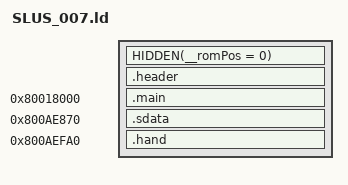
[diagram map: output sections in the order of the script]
SECTIONS
{
    HIDDEN(__romPos = 0);
    _gp = 0x800AE870;
    header_ROM_START = __romPos;
    header_VRAM = ADDR(.header);
    .header : AT(header_ROM_START) SUBALIGN(16)
    {
        FILL(0x00000000);
        header_DATA_START = .;
        build/assets/header.bin.o(.data);
        header_DATA_END = .;
        header_DATA_SIZE = ABSOLUTE(header_DATA_END - header_DATA_START);
    }
    __romPos += SIZEOF(.header);
    header_ROM_END = __romPos;
    header_VRAM_END = .;

    main_ROM_START = __romPos;
    main_VRAM = ADDR(.main);
    .main 0x80018000 : AT(main_ROM_START) SUBALIGN(4)
    {
        FILL(0x00000000);
        main_TEXT_START = .;
        build/asm/snrelmod.s.o(.text);
        build/asm/main.s.o(.text);
        build/asm/qfr_sing.s.o(.text);
        build/asm/qflypick.s.o(.text);
        build/asm/helpcomp.s.o(.text);
        build/asm/imission.s.o(.text);
        build/asm/qmbase.s.o(.text);
        build/asm/qmjail.s.o(.text);
        build/asm/qmpower.s.o(.text);
        build/asm/qmgrav.s.o(.text);
        build/asm/qmboss.s.o(.text);
        build/asm/qmtrib.s.o(.text);
        build/asm/event.s.o(.text);
        build/asm/qevent.s.o(.text);
        build/asm/event_2.s.o(.text);
        build/asm/qevent_2.s.o(.text);
        build/asm/event_3.s.o(.text);
        build/asm/qevent_3.s.o(.text);
        build/asm/event_4.s.o(.text);
        build/asm/qevent_4.s.o(.text);
        build/asm/event_5.s.o(.text);
        build/asm/qevent_5.s.o(.text);
        build/asm/event_6.s.o(.text);
        build/asm/qevent_6.s.o(.text);
        build/asm/event_7.s.o(.text);
        build/asm/qevent_7.s.o(.text);
        build/asm/event_8.s.o(.text);
        build/asm/qevent_8.s.o(.text);
        build/asm/event_9.s.o(.text);
        build/asm/blur.s.o(.text);
        build/asm/particle.s.o(.text);
        build/asm/q2muzzle.s.o(.text);
        build/asm/input.s.o(.text);
        build/asm/qpanel.s.o(.text);
        build/asm/camera.s.o(.text);
        build/asm/qcamera.s.o(.text);
        build/asm/mainloop.s.o(.text);
        build/asm/qloop.s.o(.text);
        build/asm/qplayer.s.o(.text);
        build/asm/quake.s.o(.text);
        build/asm/game.s.o(.text);
        build/asm/spritext.s.o(.text);
        build/asm/scrnshot.s.o(.text);
        build/asm/gunsight.s.o(.text);
        build/asm/col3d.s.o(.text);
        build/asm/move3d.s.o(.text);
        build/asm/sort.s.o(.text);
        build/asm/missile.s.o(.text);
        build/asm/quakemis.s.o(.text);
        build/asm/quakegun.s.o(.text);
        build/asm/coll.s.o(.text);
        build/asm/mymatrix.s.o(.text);
        build/asm/mymath.s.o(.text);
        build/asm/creature.s.o(.text);
        build/asm/quakecre.s.o(.text);
        build/asm/q_shared.s.o(.text);
        build/asm/g_ai.s.o(.text);
        build/asm/g_misc.s.o(.text);
        build/asm/g_utils.s.o(.text);
        build/asm/m_move.s.o(.text);
        build/asm/p_trail.s.o(.text);
        build/asm/g_weapon.s.o(.text);
        build/asm/gmonster.s.o(.text);
        build/asm/g_combat.s.o(.text);
        build/asm/p_weapon.s.o(.text);
        build/asm/water.s.o(.text);
        build/asm/genefect.s.o(.text);
        build/asm/scene.s.o(.text);
        build/asm/iffload.s.o(.text);
        build/asm/subdiv.s.o(.text);
        build/asm/subdiv2.s.o(.text);
        build/asm/quatanim.s.o(.text);
        build/asm/models.s.o(.text);
        build/asm/title.s.o(.text);
        build/asm/cutquake.s.o(.text);
        build/asm/mymalloc.s.o(.text);
        build/asm/common.s.o(.text);
        build/asm/misc.s.o(.text);
        build/asm/initlev.s.o(.text);
        build/asm/cdaudio.s.o(.text);
        build/asm/nsound.s.o(.text);
        build/asm/lights.s.o(.text);
        build/asm/pal.s.o(.text);
        build/asm/cdstuff.s.o(.text);
        build/asm/draw.s.o(.text);
        build/asm/shadow.s.o(.text);
        build/asm/loadlev.s.o(.text);
        build/asm/qents.s.o(.text);
        build/asm/memory.s.o(.text);
        build/asm/memcard.s.o(.text);
        build/asm/lib_80082b84.s.o(.text);
        main_TEXT_END = .;
        main_TEXT_SIZE = ABSOLUTE(main_TEXT_END - main_TEXT_START);
        main_DATA_START = .;
        build/asm/snrelmod.s.o(.data);
        build/asm/main.s.o(.data);
        build/asm/qfr_sing.s.o(.data);
        build/asm/qflypick.s.o(.data);
        build/asm/helpcomp.s.o(.data);
        build/asm/imission.s.o(.data);
        build/asm/qmbase.s.o(.data);
        build/asm/qmjail.s.o(.data);
        build/asm/qmpower.s.o(.data);
        build/asm/qmgrav.s.o(.data);
        build/asm/qmboss.s.o(.data);
        build/asm/qmtrib.s.o(.data);
        build/asm/event.s.o(.data);
        build/asm/qevent.s.o(.data);
        build/asm/event_2.s.o(.data);
        build/asm/qevent_2.s.o(.data);
        build/asm/event_3.s.o(.data);
        build/asm/qevent_3.s.o(.data);
        build/asm/event_4.s.o(.data);
        build/asm/qevent_4.s.o(.data);
        build/asm/event_5.s.o(.data);
        build/asm/qevent_5.s.o(.data);
        build/asm/event_6.s.o(.data);
        build/asm/qevent_6.s.o(.data);
        build/asm/event_7.s.o(.data);
        build/asm/qevent_7.s.o(.data);
        build/asm/event_8.s.o(.data);
        build/asm/qevent_8.s.o(.data);
        build/asm/event_9.s.o(.data);
        build/asm/blur.s.o(.data);
        build/asm/particle.s.o(.data);
        build/asm/q2muzzle.s.o(.data);
        build/asm/input.s.o(.data);
        build/asm/qpanel.s.o(.data);
        build/asm/camera.s.o(.data);
        build/asm/qcamera.s.o(.data);
        build/asm/mainloop.s.o(.data);
        build/asm/qloop.s.o(.data);
        build/asm/qplayer.s.o(.data);
        build/asm/quake.s.o(.data);
        build/asm/game.s.o(.data);
        build/asm/spritext.s.o(.data);
        build/asm/scrnshot.s.o(.data);
        build/asm/gunsight.s.o(.data);
        build/asm/col3d.s.o(.data);
        build/asm/move3d.s.o(.data);
        build/asm/sort.s.o(.data);
        build/asm/missile.s.o(.data);
        build/asm/quakemis.s.o(.data);
        build/asm/quakegun.s.o(.data);
        build/asm/coll.s.o(.data);
        build/asm/mymatrix.s.o(.data);
        build/asm/mymath.s.o(.data);
        build/asm/creature.s.o(.data);
        build/asm/quakecre.s.o(.data);
        build/asm/q_shared.s.o(.data);
        build/asm/g_ai.s.o(.data);
        build/asm/g_misc.s.o(.data);
        build/asm/g_utils.s.o(.data);
        build/asm/m_move.s.o(.data);
        build/asm/p_trail.s.o(.data);
        build/asm/g_weapon.s.o(.data);
        build/asm/gmonster.s.o(.data);
        build/asm/g_combat.s.o(.data);
        build/asm/p_weapon.s.o(.data);
        build/asm/water.s.o(.data);
        build/asm/genefect.s.o(.data);
        build/asm/scene.s.o(.data);
        build/asm/iffload.s.o(.data);
        build/asm/subdiv.s.o(.data);
        build/asm/subdiv2.s.o(.data);
        build/asm/quatanim.s.o(.data);
        build/asm/models.s.o(.data);
        build/asm/title.s.o(.data);
        build/asm/cutquake.s.o(.data);
        build/asm/mymalloc.s.o(.data);
        build/asm/common.s.o(.data);
        build/asm/misc.s.o(.data);
        build/asm/initlev.s.o(.data);
        build/asm/cdaudio.s.o(.data);
        build/asm/nsound.s.o(.data);
        build/asm/lights.s.o(.data);
        build/asm/pal.s.o(.data);
        build/asm/cdstuff.s.o(.data);
        build/asm/draw.s.o(.data);
        build/asm/shadow.s.o(.data);
        build/asm/loadlev.s.o(.data);
        build/asm/qents.s.o(.data);
        build/asm/memory.s.o(.data);
        build/asm/memcard.s.o(.data);
        build/asm/lib_80082b84.s.o(.data);
        build/asm/data/data.data.s.o(.data);
        main_DATA_END = .;
        main_DATA_SIZE = ABSOLUTE(main_DATA_END - main_DATA_START);
        main_RODATA_START = .;
        build/asm/snrelmod.s.o(.rodata);
        build/asm/main.s.o(.rodata);
        build/asm/qfr_sing.s.o(.rodata);
        build/asm/qflypick.s.o(.rodata);
        build/asm/helpcomp.s.o(.rodata);
        build/asm/imission.s.o(.rodata);
        build/asm/qmbase.s.o(.rodata);
        build/asm/qmjail.s.o(.rodata);
        build/asm/qmpower.s.o(.rodata);
        build/asm/qmgrav.s.o(.rodata);
        build/asm/qmboss.s.o(.rodata);
        build/asm/qmtrib.s.o(.rodata);
        build/asm/event.s.o(.rodata);
        build/asm/qevent.s.o(.rodata);
        build/asm/event_2.s.o(.rodata);
        build/asm/qevent_2.s.o(.rodata);
        build/asm/event_3.s.o(.rodata);
        build/asm/qevent_3.s.o(.rodata);
        build/asm/event_4.s.o(.rodata);
        build/asm/qevent_4.s.o(.rodata);
        build/asm/event_5.s.o(.rodata);
        build/asm/qevent_5.s.o(.rodata);
        build/asm/event_6.s.o(.rodata);
        build/asm/qevent_6.s.o(.rodata);
        build/asm/event_7.s.o(.rodata);
        build/asm/qevent_7.s.o(.rodata);
        build/asm/event_8.s.o(.rodata);
        build/asm/qevent_8.s.o(.rodata);
        build/asm/event_9.s.o(.rodata);
        build/asm/blur.s.o(.rodata);
        build/asm/particle.s.o(.rodata);
        build/asm/q2muzzle.s.o(.rodata);
        build/asm/input.s.o(.rodata);
        build/asm/qpanel.s.o(.rodata);
        build/asm/camera.s.o(.rodata);
        build/asm/qcamera.s.o(.rodata);
        build/asm/mainloop.s.o(.rodata);
        build/asm/qloop.s.o(.rodata);
        build/asm/qplayer.s.o(.rodata);
        build/asm/quake.s.o(.rodata);
        build/asm/game.s.o(.rodata);
        build/asm/spritext.s.o(.rodata);
        build/asm/scrnshot.s.o(.rodata);
        build/asm/gunsight.s.o(.rodata);
        build/asm/col3d.s.o(.rodata);
        build/asm/move3d.s.o(.rodata);
        build/asm/sort.s.o(.rodata);
        build/asm/missile.s.o(.rodata);
        build/asm/quakemis.s.o(.rodata);
        build/asm/quakegun.s.o(.rodata);
        build/asm/coll.s.o(.rodata);
        build/asm/mymatrix.s.o(.rodata);
        build/asm/mymath.s.o(.rodata);
        build/asm/creature.s.o(.rodata);
        build/asm/quakecre.s.o(.rodata);
        build/asm/q_shared.s.o(.rodata);
        build/asm/g_ai.s.o(.rodata);
        build/asm/g_misc.s.o(.rodata);
        build/asm/g_utils.s.o(.rodata);
        build/asm/m_move.s.o(.rodata);
        build/asm/p_trail.s.o(.rodata);
        build/asm/g_weapon.s.o(.rodata);
        build/asm/gmonster.s.o(.rodata);
        build/asm/g_combat.s.o(.rodata);
        build/asm/p_weapon.s.o(.rodata);
        build/asm/water.s.o(.rodata);
        build/asm/genefect.s.o(.rodata);
        build/asm/scene.s.o(.rodata);
        build/asm/iffload.s.o(.rodata);
        build/asm/subdiv.s.o(.rodata);
        build/asm/subdiv2.s.o(.rodata);
        build/asm/quatanim.s.o(.rodata);
        build/asm/models.s.o(.rodata);
        build/asm/title.s.o(.rodata);
        build/asm/cutquake.s.o(.rodata);
        build/asm/mymalloc.s.o(.rodata);
        build/asm/common.s.o(.rodata);
        build/asm/misc.s.o(.rodata);
        build/asm/initlev.s.o(.rodata);
        build/asm/cdaudio.s.o(.rodata);
        build/asm/nsound.s.o(.rodata);
        build/asm/lights.s.o(.rodata);
        build/asm/pal.s.o(.rodata);
        build/asm/cdstuff.s.o(.rodata);
        build/asm/draw.s.o(.rodata);
        build/asm/shadow.s.o(.rodata);
        build/asm/loadlev.s.o(.rodata);
        build/asm/qents.s.o(.rodata);
        build/asm/memory.s.o(.rodata);
        build/asm/memcard.s.o(.rodata);
        build/asm/lib_80082b84.s.o(.rodata);
        build/asm/data/rodata.rodata.s.o(.rodata);
        main_RODATA_END = .;
        main_RODATA_SIZE = ABSOLUTE(main_RODATA_END - main_RODATA_START);
        main_BSS_START = .;
        build/asm/snrelmod.s.o(.bss);
        build/asm/main.s.o(.bss);
        build/asm/qfr_sing.s.o(.bss);
        build/asm/qflypick.s.o(.bss);
        build/asm/helpcomp.s.o(.bss);
        build/asm/imission.s.o(.bss);
        build/asm/qmbase.s.o(.bss);
        build/asm/qmjail.s.o(.bss);
        build/asm/qmpower.s.o(.bss);
        build/asm/qmgrav.s.o(.bss);
        build/asm/qmboss.s.o(.bss);
        build/asm/qmtrib.s.o(.bss);
        build/asm/event.s.o(.bss);
        build/asm/qevent.s.o(.bss);
        build/asm/event_2.s.o(.bss);
        build/asm/qevent_2.s.o(.bss);
        build/asm/event_3.s.o(.bss);
        build/asm/qevent_3.s.o(.bss);
        build/asm/event_4.s.o(.bss);
        build/asm/qevent_4.s.o(.bss);
        build/asm/event_5.s.o(.bss);
        build/asm/qevent_5.s.o(.bss);
        build/asm/event_6.s.o(.bss);
        build/asm/qevent_6.s.o(.bss);
        build/asm/event_7.s.o(.bss);
        build/asm/qevent_7.s.o(.bss);
        build/asm/event_8.s.o(.bss);
        build/asm/qevent_8.s.o(.bss);
        build/asm/event_9.s.o(.bss);
        build/asm/blur.s.o(.bss);
        build/asm/particle.s.o(.bss);
        build/asm/q2muzzle.s.o(.bss);
        build/asm/input.s.o(.bss);
        build/asm/qpanel.s.o(.bss);
        build/asm/camera.s.o(.bss);
        build/asm/qcamera.s.o(.bss);
        build/asm/mainloop.s.o(.bss);
        build/asm/qloop.s.o(.bss);
        build/asm/qplayer.s.o(.bss);
        build/asm/quake.s.o(.bss);
        build/asm/game.s.o(.bss);
        build/asm/spritext.s.o(.bss);
        build/asm/scrnshot.s.o(.bss);
        build/asm/gunsight.s.o(.bss);
        build/asm/col3d.s.o(.bss);
        build/asm/move3d.s.o(.bss);
        build/asm/sort.s.o(.bss);
        build/asm/missile.s.o(.bss);
        build/asm/quakemis.s.o(.bss);
        build/asm/quakegun.s.o(.bss);
        build/asm/coll.s.o(.bss);
        build/asm/mymatrix.s.o(.bss);
        build/asm/mymath.s.o(.bss);
        build/asm/creature.s.o(.bss);
        build/asm/quakecre.s.o(.bss);
        build/asm/q_shared.s.o(.bss);
        build/asm/g_ai.s.o(.bss);
        build/asm/g_misc.s.o(.bss);
        build/asm/g_utils.s.o(.bss);
        build/asm/m_move.s.o(.bss);
        build/asm/p_trail.s.o(.bss);
        build/asm/g_weapon.s.o(.bss);
        build/asm/gmonster.s.o(.bss);
        build/asm/g_combat.s.o(.bss);
        build/asm/p_weapon.s.o(.bss);
        build/asm/water.s.o(.bss);
        build/asm/genefect.s.o(.bss);
        build/asm/scene.s.o(.bss);
        build/asm/iffload.s.o(.bss);
        build/asm/subdiv.s.o(.bss);
        build/asm/subdiv2.s.o(.bss);
        build/asm/quatanim.s.o(.bss);
        build/asm/models.s.o(.bss);
        build/asm/title.s.o(.bss);
        build/asm/cutquake.s.o(.bss);
        build/asm/mymalloc.s.o(.bss);
        build/asm/common.s.o(.bss);
        build/asm/misc.s.o(.bss);
        build/asm/initlev.s.o(.bss);
        build/asm/cdaudio.s.o(.bss);
        build/asm/nsound.s.o(.bss);
        build/asm/lights.s.o(.bss);
        build/asm/pal.s.o(.bss);
        build/asm/cdstuff.s.o(.bss);
        build/asm/draw.s.o(.bss);
        build/asm/shadow.s.o(.bss);
        build/asm/loadlev.s.o(.bss);
        build/asm/qents.s.o(.bss);
        build/asm/memory.s.o(.bss);
        build/asm/memcard.s.o(.bss);
        build/asm/lib_80082b84.s.o(.bss);
        main_BSS_END = .;
        main_BSS_SIZE = ABSOLUTE(main_BSS_END - main_BSS_START);
    }
    __romPos += SIZEOF(.main);
    __romPos = ALIGN(__romPos, 16);
    main_ROM_END = __romPos;
    main_VRAM_END = .;

    sdata_ROM_START = __romPos;
    sdata_VRAM = ADDR(.sdata);
    .sdata 0x800AE870 : AT(sdata_ROM_START) SUBALIGN(4)
    {
        FILL(0x00000000);
        sdata_DATA_START = .;
        build/asm/data/sdata.data.s.o(.data);
        sdata_DATA_END = .;
        sdata_DATA_SIZE = ABSOLUTE(sdata_DATA_END - sdata_DATA_START);
    }
    __romPos += SIZEOF(.sdata);
    __romPos = ALIGN(__romPos, 16);
    sdata_ROM_END = __romPos;
    sdata_VRAM_END = .;

    hand_ROM_START = __romPos;
    hand_VRAM = ADDR(.hand);
    .hand 0x800AEFA0 : AT(hand_ROM_START) SUBALIGN(4)
    {
        FILL(0x00000000);
        hand_TEXT_START = .;
        build/asm/hand_asm.s.o(.text);
        hand_TEXT_END = .;
        hand_TEXT_SIZE = ABSOLUTE(hand_TEXT_END - hand_TEXT_START);
        hand_DATA_START = .;
        build/asm/hand_asm.s.o(.data);
        build/asm/data/sbss_in_image.data.s.o(.data);
        hand_DATA_END = .;
        hand_DATA_SIZE = ABSOLUTE(hand_DATA_END - hand_DATA_START);
        hand_RODATA_START = .;
        build/asm/hand_asm.s.o(.rodata);
        hand_RODATA_END = .;
        hand_RODATA_SIZE = ABSOLUTE(hand_RODATA_END - hand_RODATA_START);
        hand_BSS_START = .;
        build/asm/hand_asm.s.o(.bss);
        build/asm/data/bss.bss.s.o(.bss);
        hand_BSS_END = .;
        hand_BSS_SIZE = ABSOLUTE(hand_BSS_END - hand_BSS_START);
    }
    __romPos += SIZEOF(.hand);
    __romPos = ALIGN(__romPos, 16);
    hand_ROM_END = __romPos;
    hand_VRAM_END = .;

    /DISCARD/ :
    {
        *(*);
    }
}
